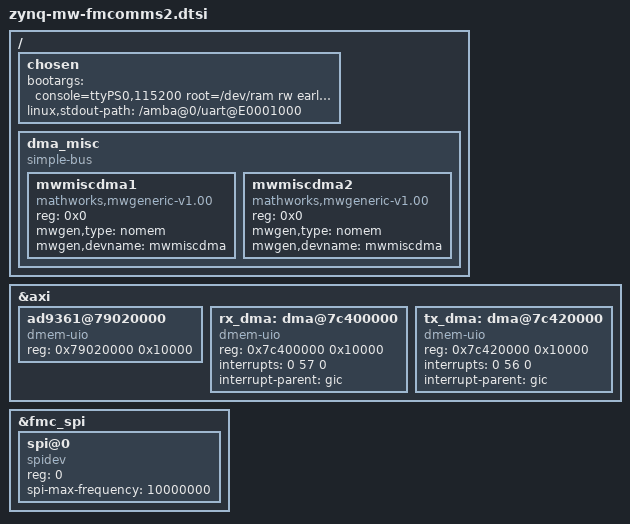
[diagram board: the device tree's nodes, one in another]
/{
	chosen {
		bootargs = "console=ttyPS0,115200 root=/dev/ram rw earlyprintk cma=128M";
		linux,stdout-path = "/amba@0/uart@E0001000";
	};

    dma_misc {
        compatible = "simple-bus";
		#address-cells = <0x1>;
		#size-cells = <0x0>;

        mwmiscdma1 {
            compatible = "mathworks,mwgeneric-v1.00";       
            reg = <0x0>;    
            mwgen,type = "nomem";            
            mwgen,devname = "mwmiscdma";            
        };
        mwmiscdma2 {
            compatible = "mathworks,mwgeneric-v1.00";       
            reg = <0x0>;    
            mwgen,type = "nomem";            
            mwgen,devname = "mwmiscdma";            
        };
    };
};

&axi {
    ad9361@79020000 {
        compatible = "dmem-uio";
        reg = < 0x79020000 0x10000>;
    };
    
    rx_dma: dma@7c400000 {
        compatible = "dmem-uio";
		reg = <0x7c400000 0x10000>;
		interrupts = <0 57 0>;
        interrupt-parent = <&gic>;
	};

	tx_dma: dma@7c420000 {
        compatible = "dmem-uio";
		reg = <0x7c420000 0x10000>;
		interrupts = <0 56 0>;
        interrupt-parent = <&gic>;
	};
};

&fmc_spi {
    status = "okay";
    spi@0 {
		compatible = "spidev";
		reg = <0>;
		spi-max-frequency = <10000000>;
	};
};

